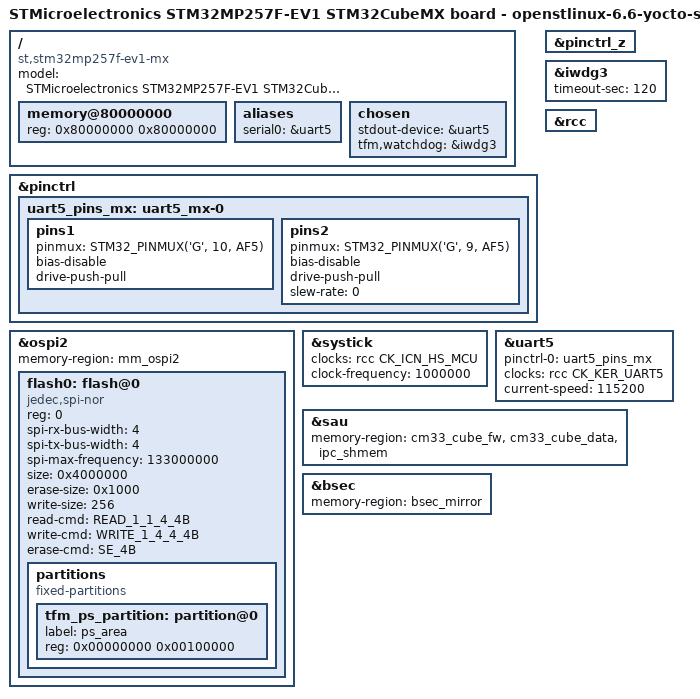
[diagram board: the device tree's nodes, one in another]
// SPDX-License-Identifier: (GPL-2.0-only OR BSD-3-Clause)
/*
 * Copyright (C) 2026, STMicroelectronics - All Rights Reserved
 * Author: STM32CubeMX code generation for STMicroelectronics.
 */

/* For more information on Device Tree configuration, please refer to
 * https://wiki.st.com/stm32mpu/wiki/Category:Device_tree_configuration
 */
/dts-v1/;
#include <dt-bindings/clock/stm32mp25-clksrc.h>
#include "dt-bindings/reset/stm32mp25-resets.h"
#include <dt-bindings/pinctrl/stm32-pinfunc.h>
#include "stm32mp257.dtsi"
#include "stm32mp25xf.dtsi"
#include "stm32mp257f-ev1-mx-rcc.dtsi"
#include "stm32mp257f-ev1-mx-resmem.dtsi"
#include "stm32mp25xxai-pinctrl.dtsi"

/* USER CODE BEGIN includes */
#include <dt-bindings/reset/st,stm32mp25-rcc.h>
#include "stm32mp257f-ev1-resmem.dtsi"
/* USER CODE END includes */

/ {
	model = "STMicroelectronics STM32MP257F-EV1 STM32CubeMX board - openstlinux-6.6-yocto-scarthgap-mpu-v26.02.18";
	compatible = "st,stm32mp257f-ev1-mx", "st,stm32mp257f-ev1", "st,stm32mp257";

	memory@80000000 {
		device_type = "memory";
		reg = <0x80000000 0x80000000>;

		/* USER CODE BEGIN memory */
		/* USER CODE END memory */
	};

	/* USER CODE BEGIN root */

	aliases{
		serial0 = &uart5;
	};

	chosen{
		stdout-device = &uart5;
		tfm,watchdog = &iwdg3;
	};
	/* USER CODE END root */

}; /*root*/

&pinctrl {
	uart5_pins_mx: uart5_mx-0 {
		pins1 {
			pinmux = <STM32_PINMUX('G', 10, AF5)>; /* UART5_RX */
			bias-disable;
			drive-push-pull;
		};
		pins2 {
			pinmux = <STM32_PINMUX('G', 9, AF5)>; /* UART5_TX */
			bias-disable;
			drive-push-pull;
			slew-rate = <0>;
		};
	};

	/* USER CODE BEGIN pinctrl */
	/* USER CODE END pinctrl */
};

&pinctrl_z {
	/* USER CODE BEGIN pinctrl_z */
	/* USER CODE END pinctrl_z */
};

&iwdg3 {
	status = "okay";

	/* USER CODE BEGIN iwdg3 */
	timeout-sec = <120>;
	/* USER CODE END iwdg3 */
};

&ospi2 {
	status = "okay";

	/* USER CODE BEGIN ospi2 */
	memory-region = <&mm_ospi2>;
	#address-cells = <1>;
	#size-cells = <0>;

	flash0:flash@0{
		compatible = "jedec,spi-nor";
		reg = <0>;
		spi-rx-bus-width = <4>;
		spi-tx-bus-width = <4>;
		spi-max-frequency = <133000000>;
		size = <0x4000000>;
		erase-size = <0x1000>;
		write-size = <256>;
		read-cmd = "READ_1_1_4_4B";
		write-cmd = "WRITE_1_4_4_4B";
		erase-cmd = "SE_4B";

		partitions{
			compatible = "fixed-partitions";
			#address-cells = <1>;
			#size-cells = <1>;

			tfm_ps_partition:partition@0{
				label = "ps_area";
				reg = <0x00000000 0x00100000>;
			};
		};
	};
	/* USER CODE END ospi2 */
};

&rcc {
	status = "okay";

	/* USER CODE BEGIN rcc */
	/* USER CODE END rcc */
};

&systick {
	status = "okay";

	/* USER CODE BEGIN systick */
	clocks = <&rcc CK_ICN_HS_MCU>;
	clock-frequency = <1000000>;
	/* USER CODE END systick */
};

&uart5 {
	pinctrl-names = "default";
	pinctrl-0 = <&uart5_pins_mx>;
	status = "okay";

	/* USER CODE BEGIN uart5 */
	clocks = <&rcc CK_KER_UART5>;
	current-speed = <115200>;
	/* USER CODE END uart5 */
};

&sau {
	memory-region = <&cm33_cube_fw>, <&cm33_cube_data>, <&ipc_shmem>;
	status = "okay";

	/* USER CODE BEGIN sau */
	/* USER CODE END sau */
};

/* USER CODE BEGIN addons */

&bsec {
	memory-region = <&bsec_mirror>;
	status = "okay";
};
/* USER CODE END addons */

